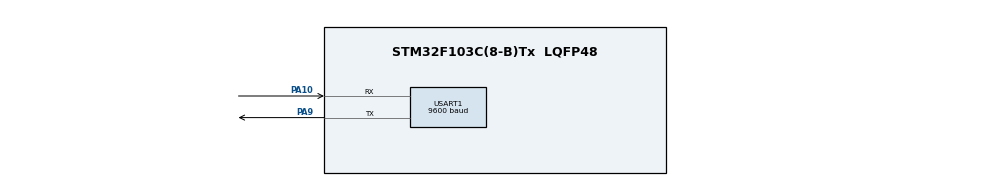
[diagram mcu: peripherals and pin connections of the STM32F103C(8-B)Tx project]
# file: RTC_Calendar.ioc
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Mcu.Family=STM32F1
Mcu.Name=STM32F103C(8-B)Tx
Mcu.Package=LQFP48
NVIC.PriorityGroup=NVIC_PRIORITYGROUP_4
PA10.Mode=Asynchronous
PA10.Signal=USART1_RX
PA13.Mode=Serial_Wire
PA13.Signal=SYS_JTMS-SWDIO
PA14.Mode=Serial_Wire
PA14.Signal=SYS_JTCK-SWCLK
PA9.Mode=Asynchronous
PA9.Signal=USART1_TX
ProjectManager.HeapSize=0x200
ProjectManager.StackSize=0x400
ProjectManager.TargetToolchain=MDK-ARM V5
RCC.APB1Freq_Value=8000000
RCC.APB2Freq_Value=8000000
RTC.Date=30
RTC.Format=RTC_FORMAT_BIN
RTC.Hours=9
RTC.Month=RTC_MONTH_MAY
RTC.WeekDay=RTC_WEEKDAY_THURSDAY
USART1.BaudRate=9600
USART1.VirtualMode=VM_ASYNC
VP_RTC_VS_RTC_Activate.Mode=RTC_Enabled
VP_RTC_VS_RTC_Calendar.Mode=RTC_Calendar
board=custom

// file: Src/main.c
/* USER CODE BEGIN Header */
/**
  ******************************************************************************
  * @file           : main.c
  * @brief          : Main program body
  ******************************************************************************
  * @attention
  *
  * <h2><center>&copy; Copyright (c) 2019 STMicroelectronics.
  * All rights reserved.</center></h2>
  *
  * This software component is licensed by ST under BSD 3-Clause license,
  * the "License"; You may not use this file except in compliance with the
  * License. You may obtain a copy of the License at:
  *                        opensource.org/licenses/BSD-3-Clause
  *
  ******************************************************************************
  */
	/* --COPYRIGHT--,
	 * Copyright (c) 2019, TAPIT Co., Ltd.
	 * https://tapit.vn
	 * ******************************* RTC_Calendar ********************************
	 *  Description: Every second will display hours, minutes, seconds on the screen
	 *  Version:    1.0
	 *  Author:     Hang Tran
	 *  Release:    May 27, 2019
	 *  Built with CubeMX Version 5.2.0 and Keil C Version 5.26.2
	 *******************************************************************************
	 */
/* USER CODE END Header */

#include "main.h"

/* USER CODE BEGIN Includes */
#include "stdbool.h"
/* USER CODE END Includes */

RTC_HandleTypeDef hrtc;

UART_HandleTypeDef huart1;

/* USER CODE BEGIN PV */
RTC_TimeTypeDef sTime = {0};
RTC_DateTypeDef DateToUpdate = {0};

uint8_t Hour;
uint8_t Minute;
uint8_t Second;

/* USER CODE END PV */

void SystemClock_Config(void);
static void MX_GPIO_Init(void);
static void MX_RTC_Init(void);
static void MX_USART1_UART_Init(void);
/* USER CODE BEGIN PFP */
bool User_InitTime(uint8_t hours, uint8_t minutes, uint8_t seconds);

/* USER CODE END PFP */

int main(void)
{

  /* MCU Configuration--------------------------------------------------------*/

  /* Reset of all peripherals, Initializes the Flash interface and the Systick. */
  HAL_Init();

  /* Configure the system clock */
  SystemClock_Config();

  /* Initialize all configured peripherals */
  MX_GPIO_Init();
  MX_RTC_Init();
  MX_USART1_UART_Init();
  /* USER CODE BEGIN 2 */
	Hour = sTime.Hours;
	Minute = sTime.Minutes;
	Second = sTime.Seconds;

  /* USER CODE END 2 */

  /* Infinite loop */
  while (1)
  {

    /* USER CODE BEGIN 3 */
		if(Second > 59)
		{
			if(Minute+1 > 59)
			{
				if(Hour+1 > 23)
				{
					Hour = (Hour+1)%24;
					Minute = (Minute+1)%60;
					Second = Second%60;
				}
				else
				{
					Hour = Hour+1;
					Minute = (Minute+1)%60;
					Second = Second%60;
				}
			}
			else
			{
				Hour = Hour;
				Minute = (Minute+1)%60;
				Second = Second%60;
			}
		}
		else
		{
			if(Minute > 59)
			{
				if(Hour+1 > 23) Hour = (Hour+1)%24;
				else Hour = Hour+1;
			}
			else
			{
				Hour = Hour;
			}
			Minute = Minute%60;
			Second = Second%60;
		}
		printf("Time: %02d:%02d:%02d\r\n",Hour,Minute,Second);
		User_InitTime(Hour,Minute,Second+1);
		HAL_Delay(1000);
  }
  /* USER CODE END 3 */
}

void SystemClock_Config(void)
{
  RCC_OscInitTypeDef RCC_OscInitStruct = {0};
  RCC_ClkInitTypeDef RCC_ClkInitStruct = {0};
  RCC_PeriphCLKInitTypeDef PeriphClkInit = {0};

  /** Initializes the CPU, AHB and APB busses clocks
  */
  RCC_OscInitStruct.OscillatorType = RCC_OSCILLATORTYPE_HSI|RCC_OSCILLATORTYPE_LSI;
  RCC_OscInitStruct.HSIState = RCC_HSI_ON;
  RCC_OscInitStruct.HSICalibrationValue = RCC_HSICALIBRATION_DEFAULT;
  RCC_OscInitStruct.LSIState = RCC_LSI_ON;
  RCC_OscInitStruct.PLL.PLLState = RCC_PLL_NONE;
  if (HAL_RCC_OscConfig(&RCC_OscInitStruct) != HAL_OK)
  {
    Error_Handler();
  }
  /** Initializes the CPU, AHB and APB busses clocks
  */
  RCC_ClkInitStruct.ClockType = RCC_CLOCKTYPE_HCLK|RCC_CLOCKTYPE_SYSCLK
                              |RCC_CLOCKTYPE_PCLK1|RCC_CLOCKTYPE_PCLK2;
  RCC_ClkInitStruct.SYSCLKSource = RCC_SYSCLKSOURCE_HSI;
  RCC_ClkInitStruct.AHBCLKDivider = RCC_SYSCLK_DIV1;
  RCC_ClkInitStruct.APB1CLKDivider = RCC_HCLK_DIV1;
  RCC_ClkInitStruct.APB2CLKDivider = RCC_HCLK_DIV1;

  if (HAL_RCC_ClockConfig(&RCC_ClkInitStruct, FLASH_LATENCY_0) != HAL_OK)
  {
    Error_Handler();
  }
  PeriphClkInit.PeriphClockSelection = RCC_PERIPHCLK_RTC;
  PeriphClkInit.RTCClockSelection = RCC_RTCCLKSOURCE_LSI;
  if (HAL_RCCEx_PeriphCLKConfig(&PeriphClkInit) != HAL_OK)
  {
    Error_Handler();
  }
}

static void MX_RTC_Init(void)
{

  /** Initialize RTC Only
  */
  hrtc.Instance = RTC;
  hrtc.Init.AsynchPrediv = RTC_AUTO_1_SECOND;
  hrtc.Init.OutPut = RTC_OUTPUTSOURCE_ALARM;
  if (HAL_RTC_Init(&hrtc) != HAL_OK)
  {
    Error_Handler();
  }

  /** Initialize RTC and set the Time and Date
  */
  sTime.Hours = 9;
  sTime.Minutes = 0;
  sTime.Seconds = 0;

  if (HAL_RTC_SetTime(&hrtc, &sTime, RTC_FORMAT_BIN) != HAL_OK)
  {
    Error_Handler();
  }
  DateToUpdate.WeekDay = RTC_WEEKDAY_THURSDAY;
  DateToUpdate.Month = RTC_MONTH_MAY;
  DateToUpdate.Date = 30;
  DateToUpdate.Year = 0;

  if (HAL_RTC_SetDate(&hrtc, &DateToUpdate, RTC_FORMAT_BIN) != HAL_OK)
  {
    Error_Handler();
  }

}

static void MX_USART1_UART_Init(void)
{

  huart1.Instance = USART1;
  huart1.Init.BaudRate = 9600;
  huart1.Init.WordLength = UART_WORDLENGTH_8B;
  huart1.Init.StopBits = UART_STOPBITS_1;
  huart1.Init.Parity = UART_PARITY_NONE;
  huart1.Init.Mode = UART_MODE_TX_RX;
  huart1.Init.HwFlowCtl = UART_HWCONTROL_NONE;
  huart1.Init.OverSampling = UART_OVERSAMPLING_16;
  if (HAL_UART_Init(&huart1) != HAL_OK)
  {
    Error_Handler();
  }

}

static void MX_GPIO_Init(void)
{

  /* GPIO Ports Clock Enable */
  __HAL_RCC_GPIOA_CLK_ENABLE();

}

/* USER CODE BEGIN 4 */
bool User_InitTime(uint8_t hours, uint8_t minutes, uint8_t seconds)
{
	sTime.Hours = hours;
	sTime.Minutes = minutes;
	sTime.Seconds = seconds;
	if (HAL_RTC_SetTime(&hrtc, &sTime, RTC_FORMAT_BIN) != HAL_OK)
  {
		return false;
  }
	Hour = sTime.Hours;
	Minute = sTime.Minutes;
	Second = sTime.Seconds;
	return true;
}

#ifdef __GNUC__
  #define PUTCHAR_PROTOTYPE int __io_putchar(int ch)
#else
  #define PUTCHAR_PROTOTYPE int fputc(int ch, FILE *f)
#endif /* __GNUC__ */
PUTCHAR_PROTOTYPE
{
    HAL_UART_Transmit(&huart1, (uint8_t *)&ch, 1, 100);
    return ch;
}

/* USER CODE END 4 */

void Error_Handler(void)
{
}

/************************ (C) COPYRIGHT STMicroelectronics *****END OF FILE****/
